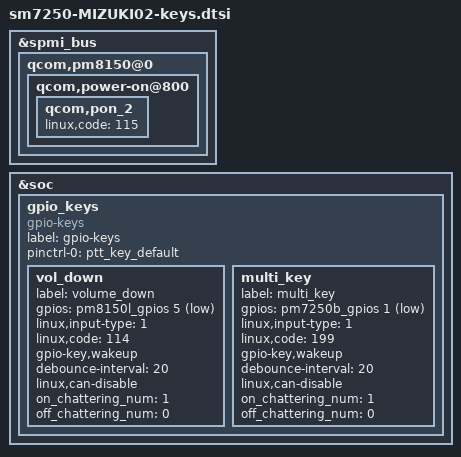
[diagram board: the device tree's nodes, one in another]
/*
 * This software is contributed or developed by KYOCERA Corporation.
 * (C) 2020 KYOCERA Corporation
 *
 * This program is free software; you can redistribute it and/or modify
 * it under the terms of the GNU General Public License version 2 and
 * only version 2 as published by the Free Software Foundation.
 *
 * This program is distributed in the hope that it will be useful,
 * but WITHOUT ANY WARRANTY; without even the implied warranty of
 * MERCHANTABILITY or FITNESS FOR A PARTICULAR PURPOSE.  See the
 * GNU General Public License for more details.
 */

&spmi_bus {
	qcom,pm8150@0 {
		qcom,power-on@800 {
			qcom,pon_2 {
				linux,code = <115>;
			};
		};
	};
};

&soc {
	gpio_keys {
		compatible = "gpio-keys";
		label = "gpio-keys";

		pinctrl-names = "default";
		pinctrl-0 = <&ptt_key_default>;

		vol_down {
			label = "volume_down";
			gpios = <&pm8150l_gpios 5 0x1>;
			linux,input-type = <1>;
			linux,code = <114>;
			gpio-key,wakeup;
			debounce-interval = <20>;
			linux,can-disable;
			on_chattering_num  = <1>;
			off_chattering_num = <0>;
		};

		multi_key  {
			label = "multi_key";
			gpios = <&pm7250b_gpios 1 0x1>;
			linux,input-type = <1>;
			linux,code = <199>;		/* KEY_CUSTOM */
			gpio-key,wakeup;
			debounce-interval = <20>;
			linux,can-disable;
			on_chattering_num  = <1>;
			off_chattering_num = <0>;
		};
	};
};

